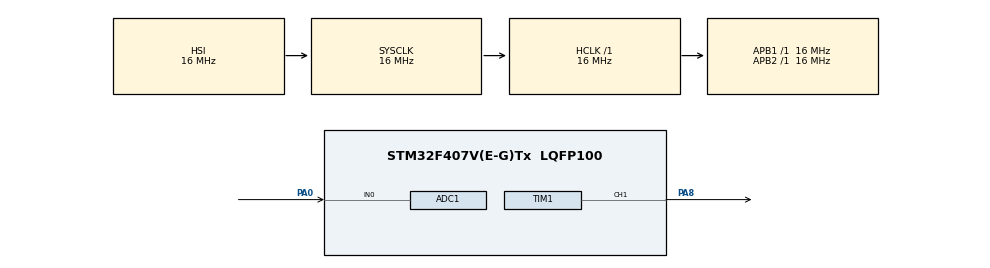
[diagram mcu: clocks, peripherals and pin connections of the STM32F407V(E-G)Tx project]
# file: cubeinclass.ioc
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Mcu.Family=STM32F4
Dma.ADC1.0.Instance=DMA2_Stream0
RCC.CortexFreq_Value=16000000
ADC1.Rank-0\#ChannelRegularConversion=1
ADC1.ContinuousConvMode=ENABLE
TIM1.Pulse-PWM\ Generation1\ CH1=250
ProjectManager.StackSize=0x400
PA0-WKUP.Signal=ADCx_IN0
Dma.ADC1.0.PeriphDataAlignment=DMA_PDATAALIGN_HALFWORD
TIM1.Prescaler=16000-1
SH.S_TIM1_CH1.0=TIM1_CH1,PWM Generation1 CH1
ProjectManager.TargetToolchain=STM32CubeIDE
Dma.ADC1.0.Mode=DMA_NORMAL
Dma.ADC1.0.Priority=DMA_PRIORITY_LOW
Dma.ADC1.0.Direction=DMA_PERIPH_TO_MEMORY
NVIC.DMA2_Stream0_IRQn=true\:0\:0\:false\:false\:true\:false\:true
RCC.LSE_VALUE=32768
Dma.ADC1.0.MemDataAlignment=DMA_MDATAALIGN_HALFWORD
RCC.AHBFreq_Value=16000000
ADC1.Channel-0\#ChannelRegularConversion=ADC_CHANNEL_0
RCC.HSE_VALUE=25000000
board=custom
RCC.VCOOutputFreq_Value=192000000
RCC.APB2Freq_Value=16000000
TIM1.Channel-PWM\ Generation1\ CH1=TIM_CHANNEL_1
Dma.ADC1.0.PeriphInc=DMA_PINC_DISABLE
PA8.Signal=S_TIM1_CH1
SH.ADCx_IN0.0=ADC1_IN0,IN0
ADC1.DMAContinuousRequests=ENABLE
Mcu.Name=STM32F407V(E-G)Tx
ADC1.SamplingTime-0\#ChannelRegularConversion=ADC_SAMPLETIME_3CYCLES
NVIC.TIM1_CC_IRQn=true\:0\:0\:false\:false\:true\:true\:true
RCC.SYSCLKFreq_VALUE=16000000
Mcu.Package=LQFP100
ADC1.master=1
Dma.ADC1.0.MemInc=DMA_MINC_ENABLE
ProjectManager.HeapSize=0x200
NVIC.TIM1_UP_TIM10_IRQn=true\:0\:0\:false\:false\:true\:true\:true
RCC.HSI_VALUE=16000000
NVIC.PriorityGroup=NVIC_PRIORITYGROUP_4
ADC1.NbrOfConversionFlag=1
Dma.ADC1.0.FIFOMode=DMA_FIFOMODE_DISABLE
TIM1.Period=1000
RCC.APB1Freq_Value=16000000
Dma.Request0=ADC1

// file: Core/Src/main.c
/* USER CODE BEGIN Header */
/**
  ******************************************************************************
  * @file           : main.c
  * @brief          : Main program body
  ******************************************************************************
  * @attention
  *
  * <h2><center>&copy; Copyright (c) 2021 STMicroelectronics.
  * All rights reserved.</center></h2>
  *
  * This software component is licensed by ST under BSD 3-Clause license,
  * the "License"; You may not use this file except in compliance with the
  * License. You may obtain a copy of the License at:
  *                        opensource.org/licenses/BSD-3-Clause
  *
  ******************************************************************************
  */
/* USER CODE END Header */
#include "main.h"

/* USER CODE BEGIN PTD */
uint16_t dmadatabuffer[1];
volatile float voltage = 0;
volatile float voltagedma = 0;
volatile float   voltagewtf = 0;
volatile float   voltagewtf2 = 0;
#define V_REF 		(float)3.3
#define RES_12B 	4096
/* USER CODE END PTD */

ADC_HandleTypeDef hadc1;
DMA_HandleTypeDef hdma_adc1;

TIM_HandleTypeDef htim1;

void SystemClock_Config(void);
static void MX_GPIO_Init(void);
static void MX_DMA_Init(void);
static void MX_ADC1_Init(void);
static void MX_TIM1_Init(void);

int main(void)
{

  /* MCU Configuration--------------------------------------------------------*/

  /* Reset of all peripherals, Initializes the Flash interface and the Systick. */
  HAL_Init();

  /* Configure the system clock */
  SystemClock_Config();

  /* Initialize all configured peripherals */
  MX_GPIO_Init();
  MX_DMA_Init();
  MX_ADC1_Init();
  MX_TIM1_Init();
  /* USER CODE BEGIN 2 */
  HAL_TIM_PWM_Start_IT(&htim1, TIM_CHANNEL_1);
  __HAL_TIM_ENABLE_IT(&htim1, TIM_IT_UPDATE);;// in order to be able to use pwmcallback

  HAL_ADC_Start_DMA(&hadc1, dmadatabuffer, 1);
  /* USER CODE END 2 */

  /* Infinite loop */
  while (1)
  {

  }
}

void SystemClock_Config(void)
{
  RCC_OscInitTypeDef RCC_OscInitStruct = {0};
  RCC_ClkInitTypeDef RCC_ClkInitStruct = {0};

  /** Configure the main internal regulator output voltage
  */
  __HAL_RCC_PWR_CLK_ENABLE();
  __HAL_PWR_VOLTAGESCALING_CONFIG(PWR_REGULATOR_VOLTAGE_SCALE1);
  /** Initializes the RCC Oscillators according to the specified parameters
  * in the RCC_OscInitTypeDef structure.
  */
  RCC_OscInitStruct.OscillatorType = RCC_OSCILLATORTYPE_HSI;
  RCC_OscInitStruct.HSIState = RCC_HSI_ON;
  RCC_OscInitStruct.HSICalibrationValue = RCC_HSICALIBRATION_DEFAULT;
  RCC_OscInitStruct.PLL.PLLState = RCC_PLL_NONE;
  if (HAL_RCC_OscConfig(&RCC_OscInitStruct) != HAL_OK)
  {
    Error_Handler();
  }
  /** Initializes the CPU, AHB and APB buses clocks
  */
  RCC_ClkInitStruct.ClockType = RCC_CLOCKTYPE_HCLK|RCC_CLOCKTYPE_SYSCLK
                              |RCC_CLOCKTYPE_PCLK1|RCC_CLOCKTYPE_PCLK2;
  RCC_ClkInitStruct.SYSCLKSource = RCC_SYSCLKSOURCE_HSI;
  RCC_ClkInitStruct.AHBCLKDivider = RCC_SYSCLK_DIV1;
  RCC_ClkInitStruct.APB1CLKDivider = RCC_HCLK_DIV1;
  RCC_ClkInitStruct.APB2CLKDivider = RCC_HCLK_DIV1;

  if (HAL_RCC_ClockConfig(&RCC_ClkInitStruct, FLASH_LATENCY_0) != HAL_OK)
  {
    Error_Handler();
  }
}

static void MX_ADC1_Init(void)
{

  ADC_ChannelConfTypeDef sConfig = {0};

  /** Configure the global features of the ADC (Clock, Resolution, Data Alignment and number of conversion)
  */
  hadc1.Instance = ADC1;
  hadc1.Init.ClockPrescaler = ADC_CLOCK_SYNC_PCLK_DIV2;
  hadc1.Init.Resolution = ADC_RESOLUTION_12B;
  hadc1.Init.ScanConvMode = DISABLE;
  hadc1.Init.ContinuousConvMode = ENABLE;
  hadc1.Init.DiscontinuousConvMode = DISABLE;
  hadc1.Init.ExternalTrigConvEdge = ADC_EXTERNALTRIGCONVEDGE_NONE;
  hadc1.Init.ExternalTrigConv = ADC_SOFTWARE_START;
  hadc1.Init.DataAlign = ADC_DATAALIGN_RIGHT;
  hadc1.Init.NbrOfConversion = 1;
  hadc1.Init.DMAContinuousRequests = ENABLE;
  hadc1.Init.EOCSelection = ADC_EOC_SINGLE_CONV;
  if (HAL_ADC_Init(&hadc1) != HAL_OK)
  {
    Error_Handler();
  }
  /** Configure for the selected ADC regular channel its corresponding rank in the sequencer and its sample time.
  */
  sConfig.Channel = ADC_CHANNEL_0;
  sConfig.Rank = 1;
  sConfig.SamplingTime = ADC_SAMPLETIME_3CYCLES;
  if (HAL_ADC_ConfigChannel(&hadc1, &sConfig) != HAL_OK)
  {
    Error_Handler();
  }

}

static void MX_TIM1_Init(void)
{

  TIM_MasterConfigTypeDef sMasterConfig = {0};
  TIM_OC_InitTypeDef sConfigOC = {0};
  TIM_BreakDeadTimeConfigTypeDef sBreakDeadTimeConfig = {0};

  htim1.Instance = TIM1;
  htim1.Init.Prescaler = 16000-1;
  htim1.Init.CounterMode = TIM_COUNTERMODE_UP;
  htim1.Init.Period = 1000;
  htim1.Init.ClockDivision = TIM_CLOCKDIVISION_DIV1;
  htim1.Init.RepetitionCounter = 0;
  htim1.Init.AutoReloadPreload = TIM_AUTORELOAD_PRELOAD_DISABLE;
  if (HAL_TIM_PWM_Init(&htim1) != HAL_OK)
  {
    Error_Handler();
  }
  sMasterConfig.MasterOutputTrigger = TIM_TRGO_RESET;
  sMasterConfig.MasterSlaveMode = TIM_MASTERSLAVEMODE_DISABLE;
  if (HAL_TIMEx_MasterConfigSynchronization(&htim1, &sMasterConfig) != HAL_OK)
  {
    Error_Handler();
  }
  sConfigOC.OCMode = TIM_OCMODE_PWM1;
  sConfigOC.Pulse = 250;
  sConfigOC.OCPolarity = TIM_OCPOLARITY_HIGH;
  sConfigOC.OCNPolarity = TIM_OCNPOLARITY_HIGH;
  sConfigOC.OCFastMode = TIM_OCFAST_DISABLE;
  sConfigOC.OCIdleState = TIM_OCIDLESTATE_RESET;
  sConfigOC.OCNIdleState = TIM_OCNIDLESTATE_RESET;
  if (HAL_TIM_PWM_ConfigChannel(&htim1, &sConfigOC, TIM_CHANNEL_1) != HAL_OK)
  {
    Error_Handler();
  }
  sBreakDeadTimeConfig.OffStateRunMode = TIM_OSSR_DISABLE;
  sBreakDeadTimeConfig.OffStateIDLEMode = TIM_OSSI_DISABLE;
  sBreakDeadTimeConfig.LockLevel = TIM_LOCKLEVEL_OFF;
  sBreakDeadTimeConfig.DeadTime = 0;
  sBreakDeadTimeConfig.BreakState = TIM_BREAK_DISABLE;
  sBreakDeadTimeConfig.BreakPolarity = TIM_BREAKPOLARITY_HIGH;
  sBreakDeadTimeConfig.AutomaticOutput = TIM_AUTOMATICOUTPUT_DISABLE;
  if (HAL_TIMEx_ConfigBreakDeadTime(&htim1, &sBreakDeadTimeConfig) != HAL_OK)
  {
    Error_Handler();
  }
  HAL_TIM_MspPostInit(&htim1);

}

static void MX_DMA_Init(void)
{

  /* DMA controller clock enable */
  __HAL_RCC_DMA2_CLK_ENABLE();

  /* DMA interrupt init */
  /* DMA2_Stream0_IRQn interrupt configuration */
  HAL_NVIC_SetPriority(DMA2_Stream0_IRQn, 0, 0);
  HAL_NVIC_EnableIRQ(DMA2_Stream0_IRQn);

}

static void MX_GPIO_Init(void)
{

  /* GPIO Ports Clock Enable */
  __HAL_RCC_GPIOA_CLK_ENABLE();

}

/* USER CODE BEGIN 4 */
void HAL_ADC_ConvCpltCallback(ADC_HandleTypeDef* hadc)
{
	 voltage = HAL_ADC_GetValue(&hadc1) / (float)RES_12B * V_REF;
		  voltagedma = dmadatabuffer[0] / (float)RES_12B * V_REF;
}
void HAL_TIM_PeriodElapsedCallback(TIM_HandleTypeDef *htim)
{
	if (voltagewtf >= 15)
			{voltagewtf=0;}

		voltagewtf++;
}
void HAL_TIM_PWM_PulseFinishedCallback(TIM_HandleTypeDef *htim)
{
	if (voltagewtf2>= 15)
			{voltagewtf2=0;}

		voltagewtf2++;
}

/* USER CODE END 4 */

void Error_Handler(void)
{
  __disable_irq();
  while (1)
  {
  }
}

/************************ (C) COPYRIGHT STMicroelectronics *****END OF FILE****/
